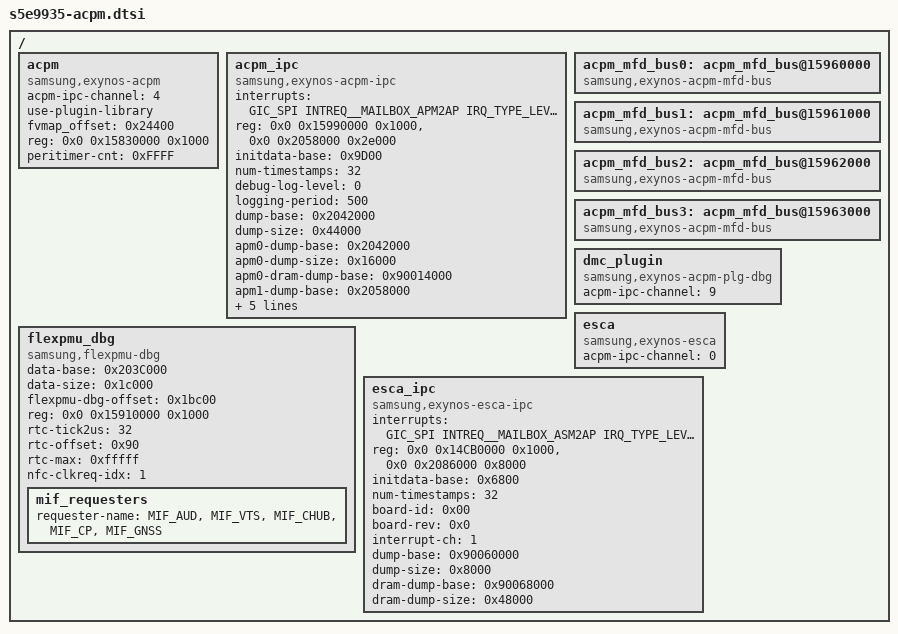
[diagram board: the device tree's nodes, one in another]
/*
 * SAMSUNG EXYNOS9935 SoC DVFS Manager device tree source
 *
 * Copyright (c) 2014 Samsung Electronics Co., Ltd.
 *		http://www.samsung.com
 *
 * SAMSUNG EXYNOS9935 SoC device nodes are listed in this file.
 * EXYNOS based board files can include this file and provide
 * values for board specfic bindings.
 *
 * This program is free software; you can redistribute it and/or modify
 * it under the terms of the GNU General Public License version 2 as
 * published by the Free Software Foundation.
 */

/ {
	acpm {
		compatible = "samsung,exynos-acpm";
		#address-cells = <2>;
		#size-cells = <1>;
		acpm-ipc-channel = <4>;
		use-plugin-library;
		fvmap_offset = <0x24400>;
		reg = <0x0 0x15830000 0x1000>;		/* TIMER_APM */
		reg-names = "timer_apm";
		peritimer-cnt = <0xFFFF>;
	};

	acpm_ipc {
		compatible = "samsung,exynos-acpm-ipc";
		#address-cells = <2>;
		#size-cells = <1>;
		interrupts = <GIC_SPI INTREQ__MAILBOX_APM2AP IRQ_TYPE_LEVEL_HIGH>;	/* AP2APM MAILBOX SPI NUM*/
		reg = <0x0 0x15990000 0x1000>,		/* AP2APM MAILBOX */
			<0x0 0x2058000 0x2e000>;	/* APM SRAM */
		initdata-base = <0x9D00>;
		num-timestamps = <32>;
		debug-log-level = <0>;
		logging-period = <500>;
		dump-base = <0x2042000>;		/* for cpif driver */
		dump-size = <0x44000>;                  /* 320KB - 16KB(SACPM) = 304KB */
		apm0-dump-base = <0x2042000>;
		apm0-dump-size = <0x16000>;
		apm0-dram-dump-base = <0x90014000>;
		apm1-dump-base = <0x2058000>;
		apm1-dump-size = <0x2e000>;
		apm1-dram-dump-base = <0x9002a000>;
		board-id = <0x10>;			/* unused */
		board-rev = <0x0>;
		interrupt-ch = <0>;
	};

	flexpmu_dbg {
		compatible = "samsung,flexpmu-dbg";
		#address-cells = <2>;
		#size-cells = <1>;
		data-base = <0x203C000>;
		data-size = <0x1c000>;
		flexpmu-dbg-offset = <0x1bc00>;
		reg = <0x0 0x15910000 0x1000>;
		rtc-tick2us = <32>;
		rtc-offset = <0x90>;
		rtc-max = <0xfffff>;
		nfc-clkreq-idx = <1>;
		mif_requesters {
			requester-name =
				"MIF_AUD",
				"MIF_VTS",
				"MIF_CHUB",
				"MIF_CP",
				"MIF_GNSS";
		};
	};

	acpm_mfd_bus0: acpm_mfd_bus@15960000 {
		compatible = "samsung,exynos-acpm-mfd-bus";
		status = "okay";
	};

	acpm_mfd_bus1: acpm_mfd_bus@15961000 {
		compatible = "samsung,exynos-acpm-mfd-bus";
		status = "okay";
	};

	acpm_mfd_bus2: acpm_mfd_bus@15962000 {
		compatible = "samsung,exynos-acpm-mfd-bus";
		status = "okay";
	};

	acpm_mfd_bus3: acpm_mfd_bus@15963000 {
		compatible = "samsung,exynos-acpm-mfd-bus";
		status = "okay";
	};

	dmc_plugin {
		compatible = "samsung,exynos-acpm-plg-dbg";
		acpm-ipc-channel = <9>;
	};

	esca {
		compatible = "samsung,exynos-esca";
		#address-cells = <2>;
		#size-cells = <1>;
		acpm-ipc-channel = <0>;
	};

	esca_ipc {
		compatible = "samsung,exynos-esca-ipc";
		#address-cells = <2>;
		#size-cells = <1>;
		interrupts = <GIC_SPI INTREQ__MAILBOX_ASM2AP IRQ_TYPE_LEVEL_HIGH>;	/* AP2ASM MAILBOX SPI NUM*/
		reg = <0x0 0x14CB0000 0x1000>,		/* AP2ASM MAILBOX */
			<0x0 0x2086000 0x8000>;		/* APM SRAM */
		initdata-base = <0x6800>;
		num-timestamps = <32>;
		board-id = <0x00>;
		board-rev = <0x0>;
		interrupt-ch = <1>;
		dump-base = <0x90060000>;
		dump-size = <0x8000>;
		dram-dump-base = <0x90068000>;
		dram-dump-size = <0x48000>;
	};
};
